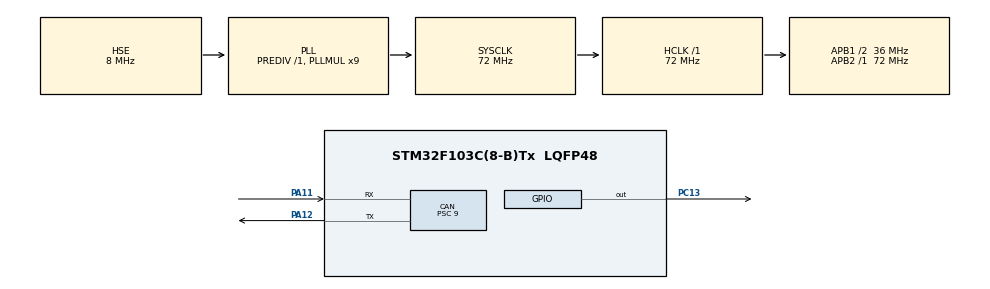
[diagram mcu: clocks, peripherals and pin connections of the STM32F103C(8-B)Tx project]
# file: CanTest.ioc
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CAN.BS1=CAN_BS1_13TQ
CAN.BS2=CAN_BS2_2TQ
CAN.CalculateTimeBit=4000
CAN.CalculateTimeQuantum=250.0
CAN.Mode=CAN_MODE_SILENT_LOOPBACK
CAN.NART=ENABLE
CAN.Prescaler=9
Mcu.Family=STM32F1
Mcu.Name=STM32F103C(8-B)Tx
Mcu.Package=LQFP48
NVIC.PriorityGroup=NVIC_PRIORITYGROUP_4
NVIC.USB_LP_CAN1_RX0_IRQn=true\:0\:0\:false\:false\:true\:true
PA11.Mode=Master
PA11.Signal=CAN_RX
PA12.Mode=Master
PA12.Signal=CAN_TX
PA13.Mode=Serial_Wire
PA13.Signal=SYS_JTMS-SWDIO
PA14.Mode=Serial_Wire
PA14.Signal=SYS_JTCK-SWCLK
PC13-TAMPER-RTC.Signal=GPIO_Output
PD0-OSC_IN.Mode=HSE-External-Oscillator
PD0-OSC_IN.Signal=RCC_OSC_IN
PD1-OSC_OUT.Mode=HSE-External-Oscillator
PD1-OSC_OUT.Signal=RCC_OSC_OUT
ProjectManager.HeapSize=0x200
ProjectManager.StackSize=0x400
ProjectManager.TargetToolchain=MDK-ARM V5
RCC.AHBFreq_Value=72000000
RCC.APB1CLKDivider=RCC_HCLK_DIV2
RCC.APB1Freq_Value=36000000
RCC.APB1TimFreq_Value=72000000
RCC.APB2Freq_Value=72000000
RCC.APB2TimFreq_Value=72000000
RCC.HCLKFreq_Value=72000000
RCC.PLLMUL=RCC_PLL_MUL9
RCC.PLLSourceVirtual=RCC_PLLSOURCE_HSE
RCC.SYSCLKFreq_VALUE=72000000
RCC.SYSCLKSource=RCC_SYSCLKSOURCE_PLLCLK
RCC.USBFreq_Value=72000000
board=custom

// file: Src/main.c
/* USER CODE BEGIN Header */
/**
  ******************************************************************************
  * @file           : main.c
  * @brief          : Main program body
  ******************************************************************************
  ** This notice applies to any and all portions of this file
  * that are not between comment pairs USER CODE BEGIN and
  * USER CODE END. Other portions of this file, whether
  * inserted by the user or by software development tools
  * are owned by their respective copyright owners.
  *
  * COPYRIGHT(c) 2020 STMicroelectronics
  *
  * Redistribution and use in source and binary forms, with or without modification,
  * are permitted provided that the following conditions are met:
  *   1. Redistributions of source code must retain the above copyright notice,
  *      this list of conditions and the following disclaimer.
  *   2. Redistributions in binary form must reproduce the above copyright notice,
  *      this list of conditions and the following disclaimer in the documentation
  *      and/or other materials provided with the distribution.
  *   3. Neither the name of STMicroelectronics nor the names of its contributors
  *      may be used to endorse or promote products derived from this software
  *      without specific prior written permission.
  *
  * THIS SOFTWARE IS PROVIDED BY THE COPYRIGHT HOLDERS AND CONTRIBUTORS "AS IS"
  * AND ANY EXPRESS OR IMPLIED WARRANTIES, INCLUDING, BUT NOT LIMITED TO, THE
  * IMPLIED WARRANTIES OF MERCHANTABILITY AND FITNESS FOR A PARTICULAR PURPOSE ARE
  * DISCLAIMED. IN NO EVENT SHALL THE COPYRIGHT HOLDER OR CONTRIBUTORS BE LIABLE
  * FOR ANY DIRECT, INDIRECT, INCIDENTAL, SPECIAL, EXEMPLARY, OR CONSEQUENTIAL
  * DAMAGES (INCLUDING, BUT NOT LIMITED TO, PROCUREMENT OF SUBSTITUTE GOODS OR
  * SERVICES; LOSS OF USE, DATA, OR PROFITS; OR BUSINESS INTERRUPTION) HOWEVER
  * CAUSED AND ON ANY THEORY OF LIABILITY, WHETHER IN CONTRACT, STRICT LIABILITY,
  * OR TORT (INCLUDING NEGLIGENCE OR OTHERWISE) ARISING IN ANY WAY OUT OF THE USE
  * OF THIS SOFTWARE, EVEN IF ADVISED OF THE POSSIBILITY OF SUCH DAMAGE.
  *
  ******************************************************************************
  */
/* USER CODE END Header */

#include "main.h"

/* USER CODE BEGIN Includes */
//https://community.st.com/s/question/0D50X00009Xkg2M/stm32f4xx-rework-of-hal-can-driver-examples
/* USER CODE END Includes */

CAN_HandleTypeDef hcan;

/* USER CODE BEGIN PV */
CAN_FilterTypeDef filterCAN;
CAN_TxHeaderTypeDef txHeader;
CAN_RxHeaderTypeDef rxHeader;

uint32_t pTxMailbox;
uint8_t txData[] = {0};
uint8_t rxData[] = {0};
/* USER CODE END PV */

void SystemClock_Config(void);
static void MX_GPIO_Init(void);
static void MX_CAN_Init(void);

int main(void)
{

  /* MCU Configuration--------------------------------------------------------*/

  /* Reset of all peripherals, Initializes the Flash interface and the Systick. */
  HAL_Init();

  /* Configure the system clock */
  SystemClock_Config();

  /* Initialize all configured peripherals */
  MX_GPIO_Init();
  MX_CAN_Init();
  /* USER CODE BEGIN 2 */
	filterCAN.FilterActivation = CAN_FILTER_ENABLE;
	filterCAN.FilterBank = 0;
	filterCAN.FilterFIFOAssignment = CAN_FILTER_FIFO0;
	filterCAN.FilterIdHigh = 0;
	filterCAN.FilterIdLow = 0;
	filterCAN.FilterMaskIdHigh = 0;
	filterCAN.FilterMaskIdLow = 0;

	filterCAN.FilterMode = CAN_FILTERMODE_IDMASK;
	filterCAN.FilterScale = CAN_FILTERSCALE_32BIT;
	HAL_CAN_ConfigFilter(&hcan, &filterCAN);

	txHeader.DLC = 8;
	txHeader.IDE = CAN_ID_STD;
	//txHeader.ExtId = CAN_ID_EXT;
	txHeader.RTR = CAN_RTR_DATA;
	txHeader.StdId = 0;
	txHeader.TransmitGlobalTime = ENABLE;

	rxHeader.DLC = 8;
	rxHeader.RTR = CAN_RTR_DATA;
	rxHeader.StdId = 0;
	rxHeader.IDE = CAN_ID_STD;

	HAL_CAN_Start(&hcan);
	HAL_CAN_ActivateNotification(&hcan,  CAN_IT_RX_FIFO0_MSG_PENDING);
  /* USER CODE END 2 */

  /* Infinite loop */
  while (1)
  {

    /* USER CODE BEGIN 3 */
		pTxMailbox = HAL_CAN_GetTxMailboxesFreeLevel(&hcan);
		if (HAL_CAN_IsTxMessagePending(&hcan, pTxMailbox) == 0){
			HAL_CAN_AddTxMessage(&hcan, &txHeader, txData, &pTxMailbox);
		}
		HAL_Delay(1000);
		txData[0]++;
  }
  /* USER CODE END 3 */
}

void SystemClock_Config(void)
{
  RCC_OscInitTypeDef RCC_OscInitStruct = {0};
  RCC_ClkInitTypeDef RCC_ClkInitStruct = {0};

  /**Initializes the CPU, AHB and APB busses clocks
  */
  RCC_OscInitStruct.OscillatorType = RCC_OSCILLATORTYPE_HSE;
  RCC_OscInitStruct.HSEState = RCC_HSE_ON;
  RCC_OscInitStruct.HSEPredivValue = RCC_HSE_PREDIV_DIV1;
  RCC_OscInitStruct.HSIState = RCC_HSI_ON;
  RCC_OscInitStruct.PLL.PLLState = RCC_PLL_ON;
  RCC_OscInitStruct.PLL.PLLSource = RCC_PLLSOURCE_HSE;
  RCC_OscInitStruct.PLL.PLLMUL = RCC_PLL_MUL9;
  if (HAL_RCC_OscConfig(&RCC_OscInitStruct) != HAL_OK)
  {
    Error_Handler();
  }
  /**Initializes the CPU, AHB and APB busses clocks
  */
  RCC_ClkInitStruct.ClockType = RCC_CLOCKTYPE_HCLK|RCC_CLOCKTYPE_SYSCLK
                              |RCC_CLOCKTYPE_PCLK1|RCC_CLOCKTYPE_PCLK2;
  RCC_ClkInitStruct.SYSCLKSource = RCC_SYSCLKSOURCE_PLLCLK;
  RCC_ClkInitStruct.AHBCLKDivider = RCC_SYSCLK_DIV1;
  RCC_ClkInitStruct.APB1CLKDivider = RCC_HCLK_DIV2;
  RCC_ClkInitStruct.APB2CLKDivider = RCC_HCLK_DIV1;

  if (HAL_RCC_ClockConfig(&RCC_ClkInitStruct, FLASH_LATENCY_2) != HAL_OK)
  {
    Error_Handler();
  }
}

static void MX_CAN_Init(void)
{

  hcan.Instance = CAN1;
  hcan.Init.Prescaler = 9;
  hcan.Init.Mode = CAN_MODE_SILENT_LOOPBACK;
  hcan.Init.SyncJumpWidth = CAN_SJW_1TQ;
  hcan.Init.TimeSeg1 = CAN_BS1_13TQ;
  hcan.Init.TimeSeg2 = CAN_BS2_2TQ;
  hcan.Init.TimeTriggeredMode = DISABLE;
  hcan.Init.AutoBusOff = DISABLE;
  hcan.Init.AutoWakeUp = DISABLE;
  hcan.Init.AutoRetransmission = ENABLE;
  hcan.Init.ReceiveFifoLocked = DISABLE;
  hcan.Init.TransmitFifoPriority = DISABLE;
  if (HAL_CAN_Init(&hcan) != HAL_OK)
  {
    Error_Handler();
  }

}

static void MX_GPIO_Init(void)
{
  GPIO_InitTypeDef GPIO_InitStruct = {0};

  /* GPIO Ports Clock Enable */
  __HAL_RCC_GPIOC_CLK_ENABLE();
  __HAL_RCC_GPIOD_CLK_ENABLE();
  __HAL_RCC_GPIOA_CLK_ENABLE();

  /*Configure GPIO pin Output Level */
  HAL_GPIO_WritePin(GPIOC, GPIO_PIN_13, GPIO_PIN_RESET);

  /*Configure GPIO pin : PC13 */
  GPIO_InitStruct.Pin = GPIO_PIN_13;
  GPIO_InitStruct.Mode = GPIO_MODE_OUTPUT_PP;
  GPIO_InitStruct.Pull = GPIO_NOPULL;
  GPIO_InitStruct.Speed = GPIO_SPEED_FREQ_LOW;
  HAL_GPIO_Init(GPIOC, &GPIO_InitStruct);

}

/* USER CODE BEGIN 4 */
	void HAL_CAN_RxFifo0FullCallback(CAN_HandleTypeDef *hcan){
		HAL_GPIO_TogglePin(GPIOC, GPIO_PIN_13);
	}
	void HAL_CAN_RxFifo0MsgPendingCallback(CAN_HandleTypeDef *hcan){
		HAL_GPIO_TogglePin(GPIOC, GPIO_PIN_13);
		//HAL_CAN_GetRxMessage(*hcan, 0, &rxHeader, rxData);
	}
/* USER CODE END 4 */

void Error_Handler(void)
{
}

/************************ (C) COPYRIGHT STMicroelectronics *****END OF FILE****/
